# PY32C6xx_DFP register map
Vendor: Puya; Series: PY32C6; File version: 1.0.0
CPU: CM0+ r0p1, little endian, no MPU, no FPU, 4 interrupt priority bits
Registers are 32-bit, read-write, reset 0x0 unless marked. A register's access mark holds for its fields unless they carry their own. Offsets are from the block's base; [hi:lo] are bit positions; {n}, {i} and the like mark numbered series.

## EXTI — External interrupt/event controller
Base 0x40021800
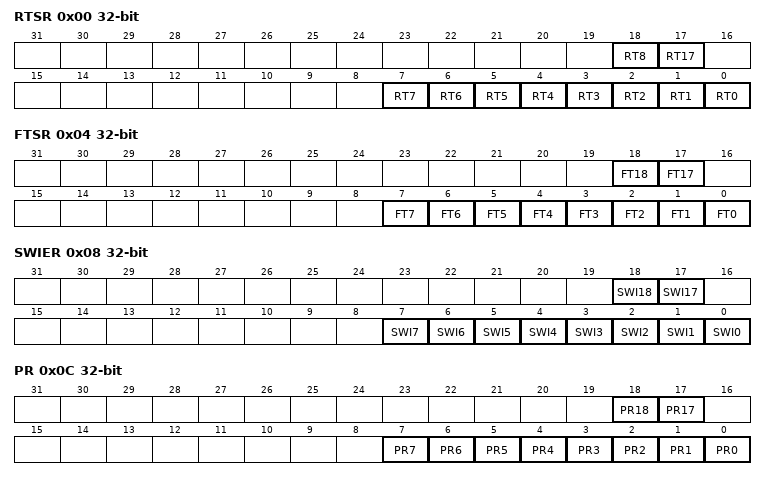
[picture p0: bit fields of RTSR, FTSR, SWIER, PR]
0x00 RTSR — EXTI rising trigger selection register
  [18] RT8 — Rising trigger event configuration bit of Configurable Event input
  [17] RT17 — Rising trigger event configuration bit of Configurable Event input
  [n] RT{n} (n=0..7) — Rising trigger event configuration bit of Configurable Event input
0x04 FTSR — EXTI falling trigger selection register
  [18] FT18 — Falling trigger event configuration bit of Configurable Event input
  [17] FT17 — Falling trigger event configuration bit of Configurable Event input
  [n] FT{n} (n=0..7) — Falling trigger event configuration bit of Configurable Event input
0x08 SWIER — EXTI software interrupt event register
  [18] SWI18 — Rising trigger event configuration bit of Configurable Event input
  [17] SWI17 — Rising trigger event configuration bit of Configurable Event input
  [n] SWI{n} (n=0..7) — Rising trigger event configuration bit of Configurable Event input
0x0C PR — EXTI pending register
  [18] PR18 — configurable event inputs x rising edge Pending bit.
  [17] PR17 — configurable event inputs x rising edge Pending bit.
  [n] PR{n} (n=0..7) — configurable event inputs x rising edge Pending bit.
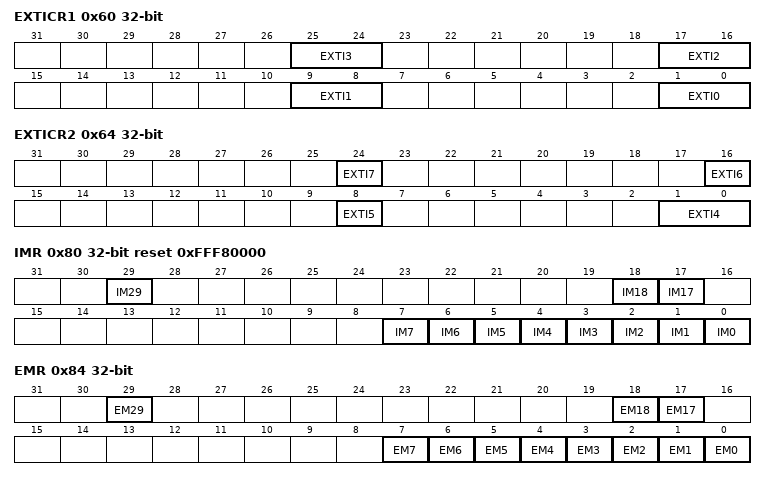
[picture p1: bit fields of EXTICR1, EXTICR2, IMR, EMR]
0x60 EXTICR1 — EXTI external interrupt selection register
  [8n+1:8n] EXTI{n} (n=0..3) — GPIO port selection
0x64 EXTICR2 — EXTI external interrupt selection register
  [24] EXTI7 — GPIO port selection
  [16] EXTI6 — GPIO port selection
  [8] EXTI5 — GPIO port selection
  [1:0] EXTI4 — GPIO port selection
0x80 IMR reset 0xFFF80000 — EXTI CPU wakeup with interrupt mask register
  [29] IM29 — CPU wakeup with interrupt mask on event input
  [18] IM18 — CPU wakeup with interrupt mask on event input
  [17] IM17 — CPU wakeup with interrupt mask on event input
  [n] IM{n} (n=0..7) — CPU wakeup with interrupt mask on event input
0x84 EMR — EXTI CPU wakeup with event mask register
  [29] EM29 — CPU wakeup with event mask on event input
  [18] EM18 — CPU wakeup with event mask on event input
  [17] EM17 — CPU wakeup with event mask on event input
  [n] EM{n} (n=0..7) — CPU wakeup with event mask on event input

## LPTIM1 — Low power timer
Base 0x40007C00
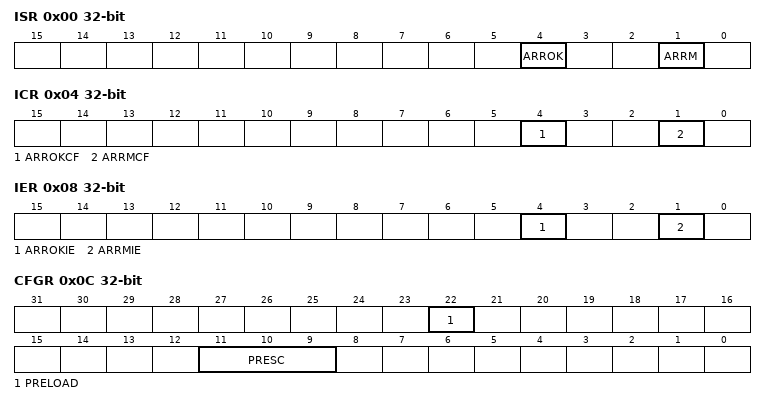
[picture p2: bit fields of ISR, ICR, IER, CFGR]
0x00 ISR ro — Interrupt and Status Register
  [4] ARROK — Autoreload match update OK
  [1] ARRM — Autoreload match
0x04 ICR wo — Interrupt Clear Register
  [4] ARROKCF — Autoreload match update OK Clear Flag
  [1] ARRMCF — Autoreload match Clear Flag
0x08 IER — Interrupt Enable Register
  [4] ARROKIE — Autoreload match update OK Interrupt Enable
  [1] ARRMIE — Autoreload matchInterrupt Enable
0x0C CFGR — Configuration Register
  [22] PRELOAD — Registers update mode
  [11:9] PRESC — Clock prescaler
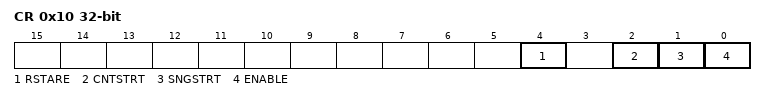
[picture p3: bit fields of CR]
0x10 CR — Control Register
  [4] RSTARE — Reset after read enable
  [2] CNTSTRT
  [1] SNGSTRT — LPTIM start in single mode
  [0] ENABLE — LPTIM Enable
0x18 ARR reset 0x1 — Autoreload Register
  [15:0] ARR — Auto reload value
0x1C CNT ro — Counter Register
  [15:0] CNT — Counter value

## USART1 — Universal synchronous asynchronous receiver transmitter
Base 0x40013800
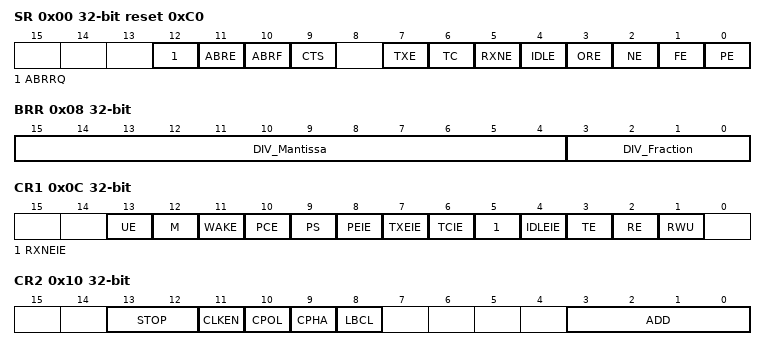
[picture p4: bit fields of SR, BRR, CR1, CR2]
0x00 SR reset 0xC0 — Status register
  [12] ABRRQ wo — Automate baudrate detection requeset
  [11] ABRE ro — Automate baudrate detection error flag
  [10] ABRF ro — Automate baudrate detection flag
  [9] CTS — CTS flag
  [7] TXE ro — Transmit data register empty
  [6] TC — Transmission complete
  [5] RXNE — Read data register not empty
  [4] IDLE ro — IDLE line detected
  [3] ORE ro — Overrun error
  [2] NE ro — Noise error flag
  [1] FE ro — Framing error
  [0] PE ro — Parity error
0x04 DR — Data register
  [8:0] DR — Data value
0x08 BRR — Baud rate register
  [15:4] DIV_Mantissa — mantissa of USARTDIV
  [3:0] DIV_Fraction — fraction of USARTDIV
0x0C CR1 — Control register 1
  [13] UE — USART enable
  [12] M — Word length
  [11] WAKE — Wakeup method
  [10] PCE — Parity control enable
  [9] PS — Parity selection
  [8] PEIE — PE interrupt enable
  [7] TXEIE — TXE interrupt enable
  [6] TCIE — Transmission complete interrupt enable
  [5] RXNEIE — RXNE interrupt enable
  [4] IDLEIE — IDLE interrupt enable
  [3] TE — Transmitter enable
  [2] RE — Receiver enable
  [1] RWU — Receiver wakeup
0x10 CR2 — Control register 2
  [13:12] STOP — STOP bits
  [11] CLKEN — Clock enable
  [10] CPOL — Clock polarity
  [9] CPHA — Clock phase
  [8] LBCL — Last bit clock pulse
  [3:0] ADD — Address of the USART node
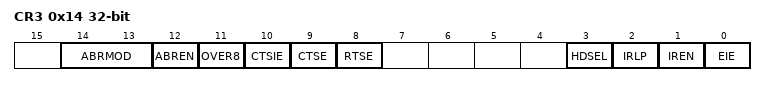
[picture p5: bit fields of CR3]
0x14 CR3 — Control register 3
  [14:13] ABRMOD — Auto baudrate mode
  [12] ABREN — Auto baudrate enable
  [11] OVER8 — Oversampling mode
  [10] CTSIE — CTS interrupt enable
  [9] CTSE — CTS enable
  [8] RTSE — RTS enable
  [3] HDSEL — Half-duplex selection
  [2] IRLP — IrDA low-power
  [1] IREN — IrDA mode enable
  [0] EIE — Error interrupt enable
